# MSP430G2X55 register map
Vendor: msp430gen; File version: v0.4.0-16-g4f822b9
Registers are 8-bit, read-write, reset 0x0 unless marked. A register's access mark holds for its fields unless they carry their own. Offsets are from the block's base; [hi:lo] are bit positions; {n}, {i} and the like mark numbered series.

## ADC10
Base 0x00000048
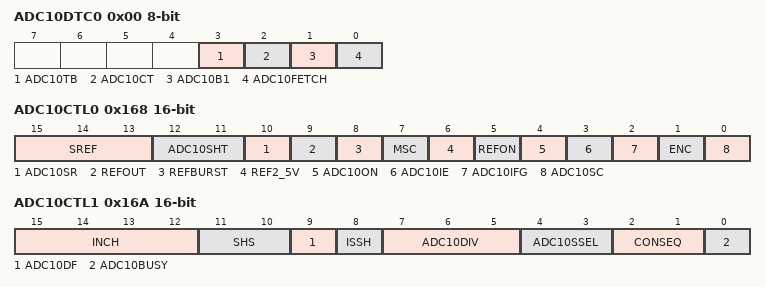
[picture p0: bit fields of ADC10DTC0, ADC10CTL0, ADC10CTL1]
0x00 ADC10DTC0 — ADC10 Data Transfer Control 0
  [3] ADC10TB — ADC10 two-block mode
  [2] ADC10CT — ADC10 continuous transfer
  [1] ADC10B1 — ADC10 block one
  [0] ADC10FETCH — This bit should normally be reset
0x01 ADC10DTC1 — ADC10 Data Transfer Control 1
  [7:0] ADC10DTC1 — ADC10 Data Transfer Control 1 register
0x02 ADC10AE0 — ADC10 Analog Enable 0
  [7:0] ADC10AE0 — ADC10 Analog Enable 0 register
0x03 ADC10AE1 — ADC10 Analog Enable 1
0x168 ADC10CTL0 16-bit — ADC10 Control 0
  [15:13] SREF — ADC10 Reference Select Bit: 0
    0=VR+ = AVCC and VR- = AVSS; 1=VR+ = VREF+ and VR- = AVSS; 2=VR+ = VEREF+ and VR- = AVSS; 3=VR+ = VEREF+ and VR- = AVSS; 4=VR+ = AVCC and VR- = VREF-/VEREF-; 5=VR+ = VREF+ and VR- = VREF-/VEREF-; 6=VR+ = VEREF+ and VR- = VREF-/VEREF-; 7=VR+ = VEREF+ and VR- = VREF-/VEREF-
  [12:11] ADC10SHT — ADC10 Sample Hold Select Bit: 0
    0=4 x ADC10CLKs; 1=8 x ADC10CLKs; 2=16 x ADC10CLKs; 3=64 x ADC10CLKs
  [10] ADC10SR — ADC10 Sampling Rate 0:200ksps / 1:50ksps
  [9] REFOUT — ADC10 Enalbe output of Ref.
  [8] REFBURST — ADC10 Reference Burst Mode
  [7] MSC — ADC10 Multiple SampleConversion
  [6] REF2_5V — ADC10 Ref 0:1.5V / 1:2.5V
  [5] REFON — ADC10 Reference on
  [4] ADC10ON — ADC10 On/Enable
  [3] ADC10IE — ADC10 Interrupt Enalbe
  [2] ADC10IFG — ADC10 Interrupt Flag
  [1] ENC — ADC10 Enable Conversion
  [0] ADC10SC — ADC10 Start Conversion
0x16A ADC10CTL1 16-bit — ADC10 Control 1
  [15:12] INCH — ADC10 Input Channel Select Bit: 0
    {v}=Selects Channel {v} (v=0..15)
  [11:10] SHS — ADC10 Sample/Hold Source Bit: 0
    0=ADC10SC; 1=TA3 OUT1; 2=TA3 OUT0; 3=TA3 OUT2
  [9] ADC10DF — ADC10 Data Format 0:binary 1:2's complement
  [8] ISSH — ADC10 Invert Sample Hold Signal
  [7:5] ADC10DIV — ADC10 Clock Divider Select Bit: 0
    {v}=ADC10 Clock Divider Select {v} (v=0..7)
  [4:3] ADC10SSEL — ADC10 Clock Source Select Bit: 0
    0=ADC10OSC; 1=ACLK; 2=MCLK; 3=SMCLK
  [2:1] CONSEQ — ADC10 Conversion Sequence Select 0
    0=Single channel single conversion; 1=Sequence of channels; 2=Repeat single channel; 3=Repeat sequence of channels
  [0] ADC10BUSY
0x16C ADC10MEM 16-bit — ADC10 Memory
  [15:0] ADC10MEM — ADC10 Memory register
0x174 ADC10SA 16-bit — ADC10 Data Transfer Start Address
  [15:0] ADC10SA — ADC10 Data Transfer Start Address register

## SYSTEM_CLOCK
Base 0x00000052
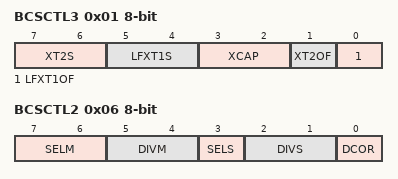
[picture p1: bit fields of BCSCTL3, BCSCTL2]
0x01 BCSCTL3 — Basic Clock System Control 3
  [7:6] XT2S — Mode 0 for XT2
    0=Mode 0 for XT2 : 0.4 - 1 MHz; 1=Mode 1 for XT2 : 1 - 4 MHz; 2=Mode 2 for XT2 : 2 - 16 MHz; 3=Mode 3 for XT2 : Digital input signal
  [5:4] LFXT1S — Mode 0 for LFXT1 (XTS = 0)
    0=Mode 0 for LFXT1 : Normal operation; 1=Mode 1 for LFXT1 : Reserved; 2=Mode 2 for LFXT1 : VLO; 3=Mode 3 for LFXT1 : Digital input signal
  [3:2] XCAP — XIN/XOUT Cap 0
    0=XIN/XOUT Cap : 0 pF; 1=XIN/XOUT Cap : 6 pF; 2=XIN/XOUT Cap : 10 pF; 3=XIN/XOUT Cap : 12.5 pF
  [1] XT2OF — High frequency oscillator 2 fault flag
  [0] LFXT1OF — Low/high Frequency Oscillator Fault Flag
0x04 DCOCTL — DCO Clock Frequency Control
  [7:5] DCO — DCO Select Bit 0
  [7:0] DCOCTL — DCO Clock Frequency Control register
  [4:0] MOD — Modulation Bit 0
0x05 BCSCTL1 — Basic Clock System Control 1
  [7] XT2OFF — Enable XT2CLK
  [6] XTS — LFXTCLK 0:Low Freq. / 1: High Freq.
  [5:4] DIVA — ACLK Divider 0
    0=ACLK Divider 0: /1; 1=ACLK Divider 1: /2; 2=ACLK Divider 2: /4; 3=ACLK Divider 3: /8
  [7:0] BCSCTL1 — Basic Clock System Control 1 register
  [3:0] RSEL — Range Select Bit 0
0x06 BCSCTL2 — Basic Clock System Control 2
  [7:6] SELM — MCLK Source Select 0
    0=MCLK Source Select 0: DCOCLK; 1=MCLK Source Select 1: DCOCLK; 2=MCLK Source Select 2: XT2CLK/LFXTCLK; 3=MCLK Source Select 3: LFXTCLK
  [5:4] DIVM — MCLK Divider 0
    0=MCLK Divider 0: /1; 1=MCLK Divider 1: /2; 2=MCLK Divider 2: /4; 3=MCLK Divider 3: /8
  [3] SELS — SMCLK Source Select 0:DCOCLK / 1:XT2CLK/LFXTCLK
  [2:1] DIVS — SMCLK Divider 0
    0=SMCLK Divider 0: /1; 1=SMCLK Divider 1: /2; 2=SMCLK Divider 2: /4; 3=SMCLK Divider 3: /8
  [0] DCOR — Enable External Resistor : 1
